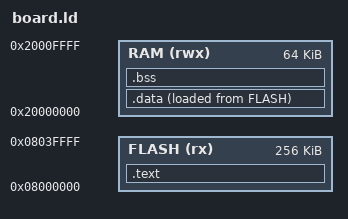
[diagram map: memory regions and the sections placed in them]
ENTRY(_start)
MEMORY {
    FLASH (rx) : ORIGIN = 0x08000000, LENGTH = 256K
    RAM (rwx) : ORIGIN = 0x20000000, LENGTH = 64K
}
SECTIONS {
    .text : { *(.text*) KEEP(*(.raw)) KEEP(*(.startup)) *(.rodata*) } > FLASH
    .data : { *(.data*) } > RAM AT > FLASH
    .bss (NOLOAD) : { *(.bss*) *(COMMON) } > RAM
}
